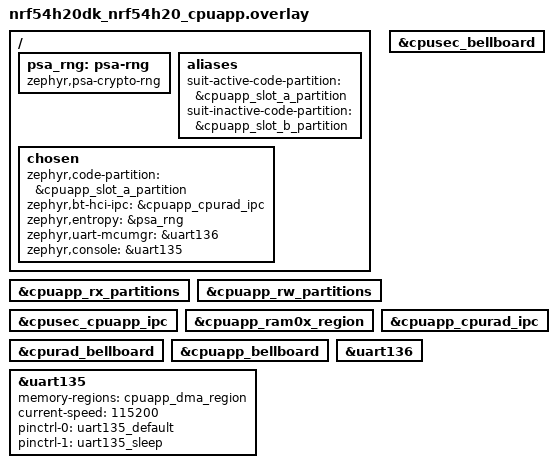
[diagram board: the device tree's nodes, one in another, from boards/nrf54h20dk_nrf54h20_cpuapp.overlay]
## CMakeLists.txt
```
#
# Copyright (c) 2025 Nordic Semiconductor ASA
#
# SPDX-License-Identifier: LicenseRef-Nordic-5-Clause
#

cmake_minimum_required(VERSION 3.13.1)

find_package(Zephyr REQUIRED HINTS $ENV{ZEPHYR_BASE})

project(suit_ab)

target_sources(app PRIVATE src/main.c)
target_sources(app PRIVATE src/suit_manifests_state.c)
target_sources(app PRIVATE src/suit_components_state.c)
target_sources(app PRIVATE src/device_management.c)
zephyr_library_include_directories(src)

zephyr_library_link_libraries(suit_manifest_variables)
zephyr_library_link_libraries(suit_ipuc)

# This project uses orginal sdk-zephyr C source code
target_include_directories(app PRIVATE $ENV{ZEPHYR_BASE}/samples/subsys/mgmt/mcumgr/smp_svr/src)
target_sources_ifdef(CONFIG_MCUMGR_TRANSPORT_BT app PRIVATE $ENV{ZEPHYR_BASE}/samples/subsys/mgmt/mcumgr/smp_svr/src/bluetooth.c)
```

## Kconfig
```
#
# Copyright (c) 2025 Nordic Semiconductor ASA
#
# SPDX-License-Identifier: LicenseRef-Nordic-5-Clause
#

config N_BLINKS
	int "Number of fast blinks"
	default 1

config ID_VAR_BOOT_STATUS
	int "Id of Manfiest-controlled variable representing a boot status"
	default 256

config ID_VAR_BOOT_PREFERENCE
	int "Id of Manfiest-controlled variable representing a boot prefrence"
	default 0

config ID_VAR_SET_TO_UPDATE
	int "Id of Manfiest-controlled variable representing image set to be updated"
	default 1

config ID_VAR_CONFIRM_SET_A
	int "Id of Manfiest-controlled variable representing after-update confirmation state for image set A"
	default 2

config ID_VAR_CONFIRM_SET_B
	int "Id of Manfiest-controlled variable representing after-update confirmation state for image set B"
	default 3

config EMULATE_APP_HEALTH_CHECK_FAILURE
	bool "Blocks confirmation of being healthy after the update"

source "Kconfig.zephyr"
```

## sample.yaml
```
#
# Copyright (c) 2025 Nordic Semiconductor ASA
#
# SPDX-License-Identifier: LicenseRef-Nordic-5-Clause
#

sample:
  name: SUIT A/B update through SMP sample
  description: Sample application that A/B updates firmware using SUIT and SMP protocol
common:
  platform_allow: nrf54h20dk/nrf54h20/cpuapp
  build_only: true
  sysbuild: true
tests:
  sample.suit.ab:
    extra_args:
    - SB_EXTRA_CONF_FILE="suit_mpi.conf"
    tags:
    - suit
    - bluetooth
    - ci_samples_suit
```

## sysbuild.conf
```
#
# Copyright (c) 2025 Nordic Semiconductor ASA
#
# SPDX-License-Identifier: LicenseRef-Nordic-5-Clause
#

SB_CONFIG_SUIT_ENVELOPE=y
SB_CONFIG_NETCORE_HCI_IPC=y

SB_CONFIG_SUIT_BUILD_AB_UPDATE=y
SB_CONFIG_SUIT_MPI_APP_LOCAL_2=y
SB_CONFIG_SUIT_MPI_RAD_LOCAL_2=y

SB_CONFIG_SUIT_BUILD_RECOVERY=y

SB_CONFIG_SUIT_ENVELOPE_APP_RECOVERY_TEMPLATE_FILENAME="app_recovery_envelope.jinja2"
```

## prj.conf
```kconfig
#
# Copyright (c) 2025 Nordic Semiconductor ASA
#
# SPDX-License-Identifier: LicenseRef-Nordic-5-Clause
#

# Enable DK LED library
CONFIG_DK_LIBRARY=y

# Enable mcumgr
CONFIG_NET_BUF=y
CONFIG_ZCBOR=y
CONFIG_ZCBOR_CANONICAL=y
CONFIG_MCUMGR=y
CONFIG_MCUMGR_SMP_LEGACY_RC_BEHAVIOUR=y
CONFIG_CRC=y

# Enable SUIT services
CONFIG_SUIT=y
CONFIG_SUIT_DFU_CANDIDATE_PROCESSING_FULL=y
CONFIG_MGMT_SUITFU=y
CONFIG_FLASH=y
CONFIG_FLASH_IPUC=y
CONFIG_SUIT_NORDIC_TOP_INDEPENDENT_UPDATE_FORBIDDEN=y
CONFIG_SUIT_CACHE_SDFW_IPUC=y

# Extended SUIT commands over USER group
CONFIG_MGMT_SUITFU_GRP_SUIT=y

# Enable bootloader identification within OS Management group
CONFIG_MCUMGR_GRP_OS=y
CONFIG_MCUMGR_GRP_OS_BOOTLOADER_INFO=y
CONFIG_MCUMGR_MGMT_NOTIFICATION_HOOKS=y
CONFIG_MCUMGR_GRP_OS_BOOTLOADER_INFO_HOOK=y

CONFIG_BT=y
CONFIG_BT_PERIPHERAL=y

# Allow for large Bluetooth data packets.
CONFIG_BT_L2CAP_TX_MTU=498
CONFIG_BT_BUF_ACL_RX_SIZE=502
CONFIG_BT_BUF_ACL_TX_SIZE=502

# Enable the Bluetooth mcumgr transport (unauthenticated).
CONFIG_MCUMGR_TRANSPORT_BT=y
CONFIG_MCUMGR_TRANSPORT_BT_PERM_RW=y
CONFIG_MCUMGR_TRANSPORT_BT_CONN_PARAM_CONTROL=y

# Enable logs over UART
CONFIG_LOG=y
CONFIG_SUIT_LOG_LEVEL_DBG=y
CONFIG_SSF_SUIT_SERVICE_LOG_LEVEL_WRN=y
CONFIG_MAIN_STACK_SIZE=4096
CONFIG_LOG_BUFFER_SIZE=8192

# Enable the mcumgr Packet Reassembly feature over Bluetooth and its configuration dependencies.
# MCUmgr buffer size is optimized to fit one SMP packet divided into five Bluetooth Write Commands,
# transmitted with the maximum possible MTU value: 498 bytes.
CONFIG_MCUMGR_TRANSPORT_BT_REASSEMBLY=y
CONFIG_MCUMGR_TRANSPORT_NETBUF_SIZE=2475
CONFIG_MCUMGR_TRANSPORT_WORKQUEUE_STACK_SIZE=4096

CONFIG_BT_DEVICE_NAME="SUIT AB Sample"

# Enable the serial mcumgr transport
CONFIG_BASE64=y
CONFIG_MCUMGR_TRANSPORT_UART=y
CONFIG_UART_MCUMGR_RX_BUF_SIZE=1040
CONFIG_MCUMGR_TRANSPORT_UART_MTU=1024
```

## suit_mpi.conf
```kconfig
#
# Copyright (c) 2025 Nordic Semiconductor ASA
#
# SPDX-License-Identifier: LicenseRef-Nordic-5-Clause
#
# ATTENTION! This is the right place to define a configuration for SUIT manifests in end-product
# and practically all config values included in that file shall be adjusted according
# to end-product needs/requirements.
# see: nrf/doc/nrf/app_dev/device_guides/nrf54h/ug_nrf54h20_suit_dfu.rst
#
# SB_CONFIG_SUIT_MPI_$(manifest)_VENDOR_NAME: Vendor-specific string *SHALL* be configured for *ALL* listed entries below.
# It may be the same value, i.e. "acme.com", for all entries, replacing existing "nordicsemi.com"
#
# SB_CONFIG_SUIT_MPI_$(manifest)_CLASS_NAME: Unique string prevents an update with firmware dedicated to other product
# Proposed schema: Manifest role + End Product model name.
# It *SHALL* be configured for *ALL* entries below, i.e.
# "nRF54H20_sample_root" replaced with "root_light_bulb_model_x123"
# "nRF54H20_sample_app" replaced with "app_A_light_bulb_model_x123"
# "nRF54H20_sample_app_local_2" replaced with "app_B_light_bulb_model_x123"
#
# Signature check policy for given manifest, select one of possible options:
# SB_CONFIG_SUIT_MPI_$(manifest)_SIGNATURE_CHECK_DISABLED=y, or
# SB_CONFIG_SUIT_MPI_$(manifest)_SIGNATURE_CHECK_ENABLED_ON_UPDATE=y, or
# SB_CONFIG_SUIT_MPI_$(manifest)_SIGNATURE_CHECK_ENABLED_ON_UPDATE_AND_BOOT=y

SB_CONFIG_SUIT_MPI_ROOT_VENDOR_NAME="nordicsemi.com"
SB_CONFIG_SUIT_MPI_ROOT_CLASS_NAME="nRF54H20_sample_root"
SB_CONFIG_SUIT_MPI_ROOT_DOWNGRADE_PREVENTION=y
SB_CONFIG_SUIT_MPI_ROOT_INDEPENDENT_UPDATE=y
SB_CONFIG_SUIT_MPI_ROOT_SIGNATURE_CHECK_ENABLED_ON_UPDATE_AND_BOOT=y

SB_CONFIG_SUIT_MPI_APP_RECOVERY=y
SB_CONFIG_SUIT_MPI_APP_RECOVERY_VENDOR_NAME="nordicsemi.com"
SB_CONFIG_SUIT_MPI_APP_RECOVERY_CLASS_NAME="nRF54H20_app_recovery"
SB_CONFIG_SUIT_MPI_APP_RECOVERY_DOWNGRADE_PREVENTION=y
SB_CONFIG_SUIT_MPI_APP_RECOVERY_INDEPENDENT_UPDATE=y
SB_CONFIG_SUIT_MPI_APP_RECOVERY_SIGNATURE_CHECK_ENABLED_ON_UPDATE_AND_BOOT=y

SB_CONFIG_SUIT_MPI_APP_LOCAL_1=y
SB_CONFIG_SUIT_MPI_APP_LOCAL_1_VENDOR_NAME="nordicsemi.com"
SB_CONFIG_SUIT_MPI_APP_LOCAL_1_CLASS_NAME="nRF54H20_sample_app"
SB_CONFIG_SUIT_MPI_APP_LOCAL_1_DOWNGRADE_PREVENTION=n
SB_CONFIG_SUIT_MPI_APP_LOCAL_1_INDEPENDENT_UPDATE=n
SB_CONFIG_SUIT_MPI_APP_LOCAL_1_SIGNATURE_CHECK_ENABLED_ON_UPDATE_AND_BOOT=y

SB_CONFIG_SUIT_MPI_APP_LOCAL_2=y
SB_CONFIG_SUIT_MPI_APP_LOCAL_2_VENDOR_NAME="nordicsemi.com"
SB_CONFIG_SUIT_MPI_APP_LOCAL_2_CLASS_NAME="nRF54H20_sample_app_local_2"
SB_CONFIG_SUIT_MPI_APP_LOCAL_2_DOWNGRADE_PREVENTION=n
SB_CONFIG_SUIT_MPI_APP_LOCAL_2_INDEPENDENT_UPDATE=n
SB_CONFIG_SUIT_MPI_APP_LOCAL_2_SIGNATURE_CHECK_ENABLED_ON_UPDATE_AND_BOOT=y

SB_CONFIG_SUIT_MPI_APP_LOCAL_3=n

SB_CONFIG_SUIT_MPI_RAD_RECOVERY=n

SB_CONFIG_SUIT_MPI_RAD_LOCAL_1=y
SB_CONFIG_SUIT_MPI_RAD_LOCAL_1_VENDOR_NAME="nordicsemi.com"
SB_CONFIG_SUIT_MPI_RAD_LOCAL_1_CLASS_NAME="nRF54H20_sample_rad"
SB_CONFIG_SUIT_MPI_RAD_LOCAL_1_DOWNGRADE_PREVENTION=n
SB_CONFIG_SUIT_MPI_RAD_LOCAL_1_INDEPENDENT_UPDATE=n
SB_CONFIG_SUIT_MPI_RAD_LOCAL_1_SIGNATURE_CHECK_ENABLED_ON_UPDATE_AND_BOOT=y

SB_CONFIG_SUIT_MPI_RAD_LOCAL_2=y
SB_CONFIG_SUIT_MPI_RAD_LOCAL_2_VENDOR_NAME="nordicsemi.com"
SB_CONFIG_SUIT_MPI_RAD_LOCAL_2_CLASS_NAME="nRF54H20_sample_rad_local_2"
SB_CONFIG_SUIT_MPI_RAD_LOCAL_2_DOWNGRADE_PREVENTION=n
SB_CONFIG_SUIT_MPI_RAD_LOCAL_2_INDEPENDENT_UPDATE=n
SB_CONFIG_SUIT_MPI_RAD_LOCAL_2_SIGNATURE_CHECK_ENABLED_ON_UPDATE_AND_BOOT=y
```

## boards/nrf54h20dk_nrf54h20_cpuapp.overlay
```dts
/*
 * Copyright (c) 2025 Nordic Semiconductor ASA
 *
 * SPDX-License-Identifier: LicenseRef-Nordic-5-Clause
 */

#include "../sysbuild/nrf54h20dk_nrf54h20_memory_map.dtsi"

/* Enable partitions, belonging to the application domain. */
&cpuapp_rx_partitions {
	status = "okay";
};

&cpuapp_rw_partitions {
	status = "okay";
};

/* Enable IPC: Application <-> Secure */
&cpusec_cpuapp_ipc {
	status = "okay";
};

&cpuapp_ram0x_region {
	status = "okay";
};

&cpusec_bellboard {
	status = "okay";
};

/* Enable IPC: Application <-> Radio */
&cpuapp_cpurad_ipc {
	status = "okay";
};

&cpurad_bellboard {
	status = "okay";
};

&cpuapp_bellboard {
	status = "okay";
};

/* Disable HW flow control on the UART 0 */
&uart136 {
	/delete-property/ hw-flow-control;
};

/ {
	psa_rng: psa-rng {
		compatible = "zephyr,psa-crypto-rng";
		status = "okay";
	};

	aliases {
		suit-active-code-partition = &cpuapp_slot_a_partition;
		suit-inactive-code-partition = &cpuapp_slot_b_partition;
	};

	chosen {
		zephyr,code-partition = &cpuapp_slot_a_partition;
		zephyr,bt-hci-ipc = &cpuapp_cpurad_ipc;
		zephyr,entropy = &psa_rng;
		zephyr,uart-mcumgr = &uart136;
	};
};

/* UART 1 is configured for App Core console output. In order to use it for other
 * purpose, i.e. to output logs form the Radio core, remove section below.
 */
&uart135 {
	status = "okay";
	memory-regions = <&cpuapp_dma_region>;
	current-speed = <115200>;
	pinctrl-0 = <&uart135_default>;
	pinctrl-1 = <&uart135_sleep>;
	pinctrl-names = "default", "sleep";

	/delete-property/ hw-flow-control;
};

/ {
	chosen {
		zephyr,console = &uart135;
	};
};
```

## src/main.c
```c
/*
 * Copyright (c) 2025 Nordic Semiconductor ASA
 *
 * SPDX-License-Identifier: LicenseRef-Nordic-5-Clause
 */

#include <suit_manifests_state.h>
#include <suit_components_state.h>
#include <device_management.h>

#include "common.h"
#include <zephyr/kernel.h>
#include <dk_buttons_and_leds.h>
#include <zephyr/logging/log.h>


#define STATUS_LEDS_THREAD_STACK_SIZE 512
#define STATUS_LEDS_THREAD_PRIORITY (CONFIG_NUM_PREEMPT_PRIORITIES - 1)
K_THREAD_STACK_DEFINE(status_leds_thread_stack_area, STATUS_LEDS_THREAD_STACK_SIZE);

LOG_MODULE_REGISTER(AB, CONFIG_SUIT_LOG_LEVEL);

static void button_handler(uint32_t button_state, uint32_t has_changed)
{
	if ((has_changed & DK_BTN4_MSK) && (button_state & DK_BTN4_MSK)) {
		toggle_preferred_boot_set();
	}
}

/**
 * Meaning of LED states on LED-s 3 and 4:
 *
 * 1) Both LEDs are on all the time: Normal mode, not degraded.
 * 2) Both leds blinking at the same time: Degraded mode.
 * 3) Only one led blinking:  Degraded mode, no radio.
 * 4) LEDs blinking one after the other:  Device in recovery mode.
 * 5) Both LEDs off:  Unrecognized state.
 */
void status_leds_thread_entry_point(void *p1, void *p2, void *p3)
{
	uint8_t sequence_led3 = 0b00;
	uint8_t sequence_led4 = 0b00;
	uint32_t boot_status = device_boot_status_get();
	uint8_t cnt = 0;

	if (device_is_in_recovery_mode()) {
		sequence_led3 = 0b01;
		sequence_led4 = 0b10;
	} else if (boot_status == BOOT_STATUS_A || boot_status == BOOT_STATUS_B) {
		sequence_led3 = 0b11;
		sequence_led4 = 0b11;
	} else if (boot_status == BOOT_STATUS_A_DEGRADED || boot_status == BOOT_STATUS_B_DEGRADED) {
		sequence_led3 = 0b10;
		sequence_led4 = 0b10;
	} else if (boot_status == BOOT_STATUS_A_NO_RADIO || boot_status == BOOT_STATUS_B_NO_RADIO) {
		sequence_led3 = 0b01;
		sequence_led4 = 0b00;
	}

	while (1) {
		if (sequence_led3 & (1 << cnt)) {
			dk_set_led_on(DK_LED3);
		} else {
			dk_set_led_off(DK_LED3);
		}

		if (sequence_led4 & (1 << cnt)) {
			dk_set_led_on(DK_LED4);
		} else {
			dk_set_led_off(DK_LED4);
		}

		k_msleep(250);

		cnt = (cnt + 1) % 2;
	}
}

int main(void)
{
	char *app_img_name = NULL;
	int ret = 0;

	ret = dk_leds_init();
	if (ret) {
		LOG_ERR("Cannot init LEDs (err: %d)\r\n", ret);
	}

	ret = dk_buttons_init(button_handler);
	if (ret) {
		LOG_ERR("Cannot init buttons (err: %d)", ret);
	}

	dk_set_led_on(DK_LED1);
	dk_set_led_on(DK_LED2);

	if (IS_ENABLED(CONFIG_MCUMGR_TRANSPORT_BT)) {
		start_smp_bluetooth_adverts();
		k_msleep(250);
	}
	printk("\n");

	suit_mainfests_state_report();
	printk("\n");

	int blinking_led = DK_LED1;

	if (DT_SAME_NODE(DT_ALIAS(suit_active_code_partition),
			 DT_NODELABEL(cpuapp_slot_a_partition))) {
		app_img_name = "A";
	} else {
		app_img_name = "B";
		blinking_led = DK_LED2;
	}

	printk("---------------------------------------------------\n");
	printk("A/B Hello world from %s, blinks: %d, img: %s\n", CONFIG_BOARD, CONFIG_N_BLINKS,
	       app_img_name);
	printk("BUILD: %s %s\n", __DATE__, __TIME__);
	printk("---------------------------------------------------\n\n");

	suit_components_state_report();
	printk("\n");

	device_boot_state_report();
	printk("\n");

	device_healthcheck();

	struct k_thread status_leds_thread_data;

	k_thread_create(&status_leds_thread_data, status_leds_thread_stack_area,
			K_THREAD_STACK_SIZEOF(status_leds_thread_stack_area),
			status_leds_thread_entry_point,
			NULL, NULL, NULL,
			STATUS_LEDS_THREAD_PRIORITY, 0, K_NO_WAIT);

	while (1) {
		for (int i = 0; i < CONFIG_N_BLINKS; i++) {
			dk_set_led_off(blinking_led);
			k_msleep(250);
			dk_set_led_on(blinking_led);
			k_msleep(250);
		}

		k_msleep(5000);
	}

	return 0;
}
```

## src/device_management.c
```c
/*
 * Copyright (c) 2025 Nordic Semiconductor ASA
 *
 * SPDX-License-Identifier: LicenseRef-Nordic-5-Clause
 */

#include <zephyr/kernel.h>
#include <suit_manifest_variables.h>
#include <device_management.h>
#include <zephyr/logging/log.h>
#include <sdfw/sdfw_services/suit_service.h>
#include <zephyr/bluetooth/bluetooth.h>
#include <mpsl/flash_sync_rpc_host.h>

LOG_MODULE_DECLARE(AB, CONFIG_SUIT_LOG_LEVEL);

#define NOT_CONFIRMED 2
#define CONFIRMED     3

#define BOOT_PREFERENCE_A 1
#define BOOT_PREFERENCE_B 2

/** @brief Radio firmware self test
 *
 * @details
 * End-device specific self test should be implemented here.
 */
static bool radio_domain_healthy(void)
{
	return bt_is_ready();
}

/** @brief Application firmware self test
 *
 * @details
 * End-device specific self test should be implemented here. Enabling
 * CONFIG_EMULATE_APP_HEALTH_CHECK_FAILURE allows to emulate a faulty
 * firmware, unable to confirm its health, and ultimately to test
 * a rollback to previous firmware after the update.
 */
static bool app_domain_healthy(void)
{
	if (IS_ENABLED(CONFIG_EMULATE_APP_HEALTH_CHECK_FAILURE)) {
		return false;
	}

	return true;
}

bool device_is_in_recovery_mode(void)
{
	static suit_boot_mode_t mode = SUIT_BOOT_MODE_UNKNOWN;
	suit_plat_err_t err = SUIT_PLAT_SUCCESS;

	if (mode == SUIT_BOOT_MODE_UNKNOWN) {
		err = suit_boot_mode_read(&mode);
		if (err != SUIT_PLAT_SUCCESS) {
			LOG_ERR("Cannot get the boot mode");
			mode = SUIT_BOOT_MODE_FAIL_STARTUP;
		}
	}

	return (mode == SUIT_BOOT_MODE_POST_INVOKE_RECOVERY);
}

uint32_t device_boot_status_get(void)
{
	suit_plat_err_t err = SUIT_PLAT_SUCCESS;
	static uint32_t mfst_var_boot_status;

	if (mfst_var_boot_status == 0) {
		err = suit_mfst_var_get(CONFIG_ID_VAR_BOOT_STATUS, &mfst_var_boot_status);
		if (err != SUIT_PLAT_SUCCESS) {
			LOG_ERR("Cannot get a device boot status");
			mfst_var_boot_status = BOOT_STATUS_CANNOT_BOOT;
		}
	}

	return mfst_var_boot_status;
}

void device_healthcheck(void)
{
	suit_plat_err_t err = SUIT_PLAT_SUCCESS;
	char *img_set = NULL;
	uint32_t mfst_var_boot_status = BOOT_STATUS_CANNOT_BOOT;
	uint32_t mfst_var_confirm_status = CONFIRMED;
	uint32_t id_var_confirm_set = CONFIG_ID_VAR_CONFIRM_SET_A;

	mfst_var_boot_status = device_boot_status_get();

	if (mfst_var_boot_status == BOOT_STATUS_CANNOT_BOOT) {
		return;
	}

	if (mfst_var_boot_status == BOOT_STATUS_A_NO_RADIO
	    || mfst_var_boot_status == BOOT_STATUS_B_NO_RADIO) {
		/* Disable flash synchronization with radio core,
		 * as radio core is not running.
		 */
		flash_sync_rpc_host_sync_enable(false);
	}

	/* Confirming only in non-degraded boot states
	 */
	if (DT_SAME_NODE(DT_ALIAS(suit_active_code_partition),
			 DT_NODELABEL(cpuapp_slot_a_partition))) {
		if (mfst_var_boot_status != BOOT_STATUS_A) {
			return;
		}
		img_set = "A";
	} else {
		if (mfst_var_boot_status != BOOT_STATUS_B) {
			return;
		}

		img_set = "B";
		id_var_confirm_set = CONFIG_ID_VAR_CONFIRM_SET_B;
	}

	err = suit_mfst_var_get(id_var_confirm_set, &mfst_var_confirm_status);
	if (err != SUIT_PLAT_SUCCESS) {
		LOG_ERR("Cannot get a confirm status");
		return;
	}

	if (mfst_var_confirm_status != CONFIRMED) {
		LOG_INF("Image set %s not confirmed yet, testing...", img_set);

		bool healthy = true;

		if (!radio_domain_healthy()) {
			LOG_ERR("Radio domain is NOT healthy");
			/* Disable flash synchronization with radio core,
			 * as radio core is not operational.
			 */
			flash_sync_rpc_host_sync_enable(false);
			healthy = false;
		}

		if (!app_domain_healthy()) {
			LOG_ERR("App domain is NOT healthy");
			healthy = false;
		}

		if (!healthy) {
			LOG_ERR("Reboot the device to try to boot from previous firmware");
			return;
		}

		LOG_INF("Confirming...");
		err = suit_mfst_var_set(id_var_confirm_set, CONFIRMED);
		if (err == SUIT_PLAT_SUCCESS) {
			LOG_INF("Confirmed\n");
		}
	}
}

void toggle_preferred_boot_set(void)
{
	suit_plat_err_t err = SUIT_PLAT_SUCCESS;
	uint32_t mfst_var_boot_preference = 0;

	err = suit_mfst_var_get(CONFIG_ID_VAR_BOOT_PREFERENCE, &mfst_var_boot_preference);
	if (err != SUIT_PLAT_SUCCESS) {
		LOG_ERR("Cannot get current boot preference");
		return;
	}

	if (mfst_var_boot_preference == BOOT_PREFERENCE_B) {
		LOG_INF("Changing a boot preference (b -> A)");
		mfst_var_boot_preference = BOOT_PREFERENCE_A;
	} else {
		LOG_INF("Changing a boot preference (a -> B)");
		mfst_var_boot_preference = BOOT_PREFERENCE_B;
	}

	err = suit_mfst_var_set(CONFIG_ID_VAR_BOOT_PREFERENCE, mfst_var_boot_preference);
	if (err == SUIT_PLAT_SUCCESS) {
		LOG_INF("restart the device to enforce\n");
	} else {
		LOG_ERR("Cannot set a boot preference");
	}
}

void device_boot_state_report(void)
{
	suit_plat_err_t err = SUIT_PLAT_SUCCESS;
	uint32_t mfst_var_boot_preference = 0;
	uint32_t mfst_var_boot_status = 0;
	uint32_t mfst_var_confirm_set_a = 0;
	uint32_t mfst_var_confirm_set_b = 0;

	if (device_is_in_recovery_mode()) {
		printk("Boot in RECOVERY mode, probably the root manifest is damaged!\n");
	}

	err = suit_mfst_var_get(CONFIG_ID_VAR_BOOT_PREFERENCE, &mfst_var_boot_preference);
	if (err == SUIT_PLAT_SUCCESS) {
		if (mfst_var_boot_preference == BOOT_PREFERENCE_B) {
			printk("Boot preference: set B\n");
		} else {
			printk("Boot preference: set A\n");
		}
	}

	mfst_var_boot_status = device_boot_status_get();

	if (mfst_var_boot_status == BOOT_STATUS_A) {
		printk("Boot status: image set A active\n");
	} else if (mfst_var_boot_status == BOOT_STATUS_B) {
		printk("Boot status: image set B active\n");
	} else if (mfst_var_boot_status == BOOT_STATUS_A_DEGRADED) {
		printk("Boot status: image set A active, degraded mode\n");
	} else if (mfst_var_boot_status == BOOT_STATUS_B_DEGRADED) {
		printk("Boot status: app image B active, degraded mode\n");
	} else if (mfst_var_boot_status == BOOT_STATUS_A_NO_RADIO) {
		printk("Boot status: app image A active, no radio, degraded mode\n");
	} else if (mfst_var_boot_status == BOOT_STATUS_B_NO_RADIO) {
		printk("Boot status: app image B active, no radio, degraded mode\n");
	} else {
		printk("Boot status: unrecognized\n");
	}

	err = suit_mfst_var_get(CONFIG_ID_VAR_CONFIRM_SET_A, &mfst_var_confirm_set_a);
	if (err == SUIT_PLAT_SUCCESS) {
		if (mfst_var_confirm_set_a == NOT_CONFIRMED) {
			printk("Confirm status set A: not confirmed\n");
		} else if (mfst_var_confirm_set_a == CONFIRMED) {
			printk("Confirm status set A: confirmed\n");
		} else {
			printk("Confirm status set A: just installed\n");
		}
	}

	err = suit_mfst_var_get(CONFIG_ID_VAR_CONFIRM_SET_B, &mfst_var_confirm_set_b);
	if (err == SUIT_PLAT_SUCCESS) {
		if (mfst_var_confirm_set_b == NOT_CONFIRMED) {
			printk("Confirm status set B: not confirmed\n");
		} else if (mfst_var_confirm_set_b == CONFIRMED) {
			printk("Confirm status set B: confirmed\n");
		} else {
			printk("Confirm status set B: just installed\n");
		}
	}
}
```

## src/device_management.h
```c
/*
 * Copyright (c) 2025 Nordic Semiconductor ASA
 *
 * SPDX-License-Identifier: LicenseRef-Nordic-5-Clause
 */

#ifndef DEVICE_MANAGEMANT_H__
#define DEVICE_MANAGEMANT_H__

#ifdef __cplusplus
extern "C" {
#endif

#include <stdint.h>
#include <stdbool.h>

/* Definitions below reflect a way of usage of manifest-controlled variables
 * in this specific application.
 */
#define BOOT_STATUS_A		1
#define BOOT_STATUS_B		2
#define BOOT_STATUS_A_DEGRADED	3
#define BOOT_STATUS_B_DEGRADED	4
#define BOOT_STATUS_A_NO_RADIO	5
#define BOOT_STATUS_B_NO_RADIO	6
#define BOOT_STATUS_CANNOT_BOOT 7

/** @brief Performs a self-tests and confirms
 * successful firmware update, if needed
 */
void device_healthcheck(void);

/** @brief Toggles preferred boot set
 */
void toggle_preferred_boot_set(void);

/** @brief Displays information about state of image sets,
 * boot preference and a boot status
 */
void device_boot_state_report(void);

/** @brief Checks if the device is in recovery mode
 */
bool device_is_in_recovery_mode(void);

/** @brief Gets the boot status of the device
 */
uint32_t device_boot_status_get(void);

#endif /* DEVICE_MANAGEMANT_H__ */
```

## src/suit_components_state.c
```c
/*
 * Copyright (c) 2025 Nordic Semiconductor ASA
 *
 * SPDX-License-Identifier: LicenseRef-Nordic-5-Clause
 */

#include <zephyr/kernel.h>
#include <suit_ipuc.h>
#include <suit_metadata.h>
#include <suit_plat_decode_util.h>
#include <suit_components_state.h>

void suit_components_state_report(void)
{
	suit_plat_err_t err = SUIT_PLAT_SUCCESS;
	size_t count = 0;

	err = suit_ipuc_get_count(&count);
	if (err == SUIT_PLAT_SUCCESS) {

		printk("In-place updateable components:\n");
		for (size_t idx = 0; idx < count; idx++) {
			struct zcbor_string component_id;
			uint8_t component_id_data[32];
			suit_manifest_role_t role = SUIT_MANIFEST_UNKNOWN;

			component_id.value = component_id_data;
			component_id.len = sizeof(component_id_data);
			err = suit_ipuc_get_info(idx, &component_id, &role);
			if (err == SUIT_PLAT_SUCCESS) {
				suit_component_type_t component_type =
					SUIT_COMPONENT_TYPE_UNSUPPORTED;

				suit_plat_decode_component_type(&component_id, &component_type);
				if (component_type == SUIT_COMPONENT_TYPE_MEM) {
					uint8_t core_id = 0;
					intptr_t run_address = 0;
					size_t slot_size = 0;

					suit_plat_decode_component_id(&component_id, &core_id,
								      &run_address, &slot_size);

					printk("MEM, 0x%08X, %d bytes, core: %d, mfst role: "
					       "0x%02X\n",
					       (unsigned int)run_address, slot_size, core_id, role);

				} else {
					printk("component_type: %d, mfst role: 0x%02X\n",
					       component_type, role);
				}
			}
		}
	}
}
```

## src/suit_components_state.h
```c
/*
 * Copyright (c) 2025 Nordic Semiconductor ASA
 *
 * SPDX-License-Identifier: LicenseRef-Nordic-5-Clause
 */

#ifndef SUIT_COMPONENTS_STATE_H__
#define SUIT_COMPONENTS_STATE_H__

#ifdef __cplusplus
extern "C" {
#endif

/** @brief Displays information about known SUIT components
 */
void suit_components_state_report(void);

#endif /* SUIT_COMPONENTS_STATE_H__ */
```

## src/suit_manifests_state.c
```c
/*
 * Copyright (c) 2025 Nordic Semiconductor ASA
 *
 * SPDX-License-Identifier: LicenseRef-Nordic-5-Clause
 */

#include <stdint.h>
#include <zephyr/kernel.h>
#include <sdfw/sdfw_services/suit_service.h>
#include <suit_manifests_state.h>

#define MAX_MANIFESTS 15

static void report_class_id(uint8_t *cid)
{

	static const uint8_t nRF54H20_sample_root_cid[] = {0x3f, 0x6a, 0x3a, 0x4d, 0xcd, 0xfa,
							   0x58, 0xc5, 0xac, 0xce, 0xf9, 0xf5,
							   0x84, 0xc4, 0x11, 0x24};

	static const uint8_t nRF54H20_sample_app_recovery_cid[] = {
		0xA3, 0x7B, 0x77, 0xB0, 0x87, 0x0E, 0x57, 0x49,
		0xA8, 0x64, 0xF1, 0x44, 0x4A, 0xAF, 0xF5, 0x47};

	static const uint8_t nRF54H20_sample_app_cid[] = {0x08, 0xc1, 0xb5, 0x99, 0x55, 0xe8,
							  0x5f, 0xbc, 0x9e, 0x76, 0x7b, 0xc2,
							  0x9c, 0xe1, 0xb0, 0x4d};
	static const uint8_t nRF54H20_sample_app2_cid[] = {0x51, 0xde, 0x10, 0xb8, 0xee, 0x2e,
							   0x5b, 0x4b, 0x80, 0xee, 0x53, 0x4a,
							   0x4a, 0x3c, 0x04, 0xfc};

	static const uint8_t nRF54H20_sample_app3_cid[] = {0x2D, 0xCA, 0x15, 0xA5, 0xA3, 0x2E,
							   0x5A, 0x71, 0xBE, 0x54, 0xBA, 0x07,
							   0xBB, 0xAF, 0xAE, 0x27};

	static const uint8_t nRF54H20_sample_rad_recovery_cid[] = {
		0x58, 0x00, 0x98, 0xAE, 0xB2, 0x40, 0x50, 0x66,
		0xAF, 0x45, 0x57, 0x33, 0x25, 0xFC, 0x39, 0xF6};

	static const uint8_t nRF54H20_sample_rad_cid[] = {0x81, 0x6a, 0xa0, 0xa0, 0xaf, 0x11,
							  0x5e, 0xf2, 0x85, 0x8a, 0xfe, 0xb6,
							  0x68, 0xb2, 0xe9, 0xc9};
	static const uint8_t nRF54H20_sample_rad2_cid[] = {0x0a, 0xa4, 0xbe, 0x57, 0xb3, 0x1e,
							   0x57, 0x9c, 0xab, 0x81, 0x13, 0xbd,
							   0x90, 0xe1, 0x6e, 0xf7};
	static const uint8_t nRF54H20_nordic_top_cid[] = {0xf0, 0x3d, 0x38, 0x5e, 0xa7, 0x31,
							  0x56, 0x05, 0xb1, 0x5d, 0x03, 0x7f,
							  0x6d, 0xa6, 0x09, 0x7f};
	static const uint8_t nRF54H20_sys_cid[] = {0xc0, 0x8a, 0x25, 0xd7, 0x35, 0xe6, 0x59, 0x2c,
						   0xb7, 0xad, 0x43, 0xac, 0xc8, 0xd1, 0xd1, 0xc8};
	static const uint8_t nRF54H20_sec_cid[] = {0xd9, 0x6b, 0x40, 0xb7, 0x09, 0x2b, 0x5c, 0xd1,
						   0xa5, 0x9f, 0x9a, 0xf8, 0x0c, 0x33, 0x7e, 0xba};

	printk(" class ID:  %02X%02X%02X%02X-%02X%02X-%02X%02X-%02X%02X-%02X%02X%02X%02X%02X%02X",
	       cid[0], cid[1], cid[2], cid[3], cid[4], cid[5], cid[6], cid[7], cid[8], cid[9],
	       cid[10], cid[11], cid[12], cid[13], cid[14], cid[15]);

	if (memcmp(nRF54H20_sample_root_cid, cid, 16) == 0) {
		printk(" (nRF54H20_sample_root) - TO BE CHANGED for end product!!!\n");
	} else if (memcmp(nRF54H20_sample_app_recovery_cid, cid, 16) == 0) {
		printk(" (nRF54H20_app_recovery) - TO BE CHANGED for end product!!!\n");
	} else if (memcmp(nRF54H20_sample_app_cid, cid, 16) == 0) {
		printk(" (nRF54H20_sample_app) - TO BE CHANGED for end product!!!\n");
	} else if (memcmp(nRF54H20_sample_app2_cid, cid, 16) == 0) {
		printk(" (nRF54H20_sample_app_local_2) - TO BE CHANGED for end product!!!\n");
	} else if (memcmp(nRF54H20_sample_app3_cid, cid, 16) == 0) {
		printk(" (nRF54H20_sample_app_local_3) - TO BE CHANGED for end product!!!\n");
	} else if (memcmp(nRF54H20_sample_rad_recovery_cid, cid, 16) == 0) {
		printk(" (nRF54H20_sample_rad_recovery) - TO BE CHANGED for end product!!!\n");
	} else if (memcmp(nRF54H20_sample_rad_cid, cid, 16) == 0) {
		printk(" (nRF54H20_sample_rad) - TO BE CHANGED for end product!!!\n");
	} else if (memcmp(nRF54H20_sample_rad2_cid, cid, 16) == 0) {
		printk(" (nRF54H20_sample_rad2) - TO BE CHANGED for end product!!!\n");
	} else if (memcmp(nRF54H20_nordic_top_cid, cid, 16) == 0) {
		printk(" (nRF54H20_nordic_top)\n");
	} else if (memcmp(nRF54H20_sys_cid, cid, 16) == 0) {
		printk(" (nRF54H20_sys)\n");
	} else if (memcmp(nRF54H20_sec_cid, cid, 16) == 0) {
		printk(" (nRF54H20_sec)\n");
	} else {
		printk("\n");
	}
}

static void report_vendor_id(uint8_t *vid, suit_manifest_role_t role)
{

	static const uint8_t nordic_vid[] = {0x76, 0x17, 0xda, 0xa5, 0x71, 0xfd, 0x5a, 0x85,
					     0x8f, 0x94, 0xe2, 0x8d, 0x73, 0x5c, 0xe9, 0xf4};

	printk(" vendor ID: %02X%02X%02X%02X-%02X%02X-%02X%02X-%02X%02X-%02X%02X%02X%02X%02X%02X",
	       vid[0], vid[1], vid[2], vid[3], vid[4], vid[5], vid[6], vid[7], vid[8], vid[9],
	       vid[10], vid[11], vid[12], vid[13], vid[14], vid[15]);

	if (memcmp(nordic_vid, vid, 16) == 0) {

		if (((role & 0xF0) == SUIT_MANIFEST_DOMAIN_APP) ||
		    ((role & 0xF0) == SUIT_MANIFEST_DOMAIN_RAD)) {
			printk(" (nordicsemi.com) - TO BE CHANGED for end product!!!\n");
		} else {
			printk(" (nordicsemi.com)\n");
		}
	} else {
		printk("\n");
	}
}

static void report_role(suit_manifest_role_t role)
{
	printk("   role: 0x%02x", role);

	if (role == SUIT_MANIFEST_SEC_TOP) {
		printk(" (Nordic Top Manifest)\n");
	} else if (role == SUIT_MANIFEST_SEC_SDFW) {
		printk(" (SDFW and SDFW recovery updates)\n");
	} else if (role == SUIT_MANIFEST_SEC_SYSCTRL) {
		printk(" (System Controller Manifest)\n");
	} else if (role == SUIT_MANIFEST_APP_ROOT) {
		printk(" (Root Manifest)\n");
	} else if (role == SUIT_MANIFEST_APP_RECOVERY) {
		printk(" (Application Recovery Manifest)\n");
	} else if (role >= SUIT_MANIFEST_APP_LOCAL_1 && role <= SUIT_MANIFEST_APP_LOCAL_3) {
		printk(" (Application Local Manifest)\n");
	} else if (role == SUIT_MANIFEST_RAD_RECOVERY) {
		printk(" (Radio Recovery Manifest)\n");
	} else if (role >= SUIT_MANIFEST_RAD_LOCAL_1 && role <= SUIT_MANIFEST_RAD_LOCAL_2) {
		printk(" (Radio Local Manifest)\n");
	} else {
		printk("\n");
	}
}

static void report_downgrade_prevention_policy(suit_downgrade_prevention_policy_t policy)
{
	printk("   downgrade prevention policy:");

	if (policy == SUIT_DOWNGRADE_PREVENTION_DISABLED) {
		printk(" downgrade allowed\n");
	} else if (policy == SUIT_DOWNGRADE_PREVENTION_ENABLED) {
		printk(" downgrade forbidden\n");
	} else {
		printk(" invalid!\n");
	}
}

static void report_independent_updateability_policy(suit_independent_updateability_policy_t policy)
{
	printk("   independent updateability policy:");

	if (policy == SUIT_INDEPENDENT_UPDATE_DENIED) {
		printk(" independent update forbidden\n");
	} else if (policy == SUIT_INDEPENDENT_UPDATE_ALLOWED) {
		printk(" independent update allowed\n");
	} else {
		printk(" invalid!\n");
	}
}

static void report_signature_verification_policy(suit_signature_verification_policy_t policy)
{
	printk("   signature verification policy:");

	if (policy == SUIT_SIGNATURE_CHECK_DISABLED) {
		printk(" signature verification disabled\n");
	} else if (policy == SUIT_SIGNATURE_CHECK_ENABLED_ON_UPDATE) {
		printk(" signature verification on update\n");
	} else if (policy == SUIT_SIGNATURE_CHECK_ENABLED_ON_UPDATE_AND_BOOT) {
		printk(" signature verification on update and boot\n");
	} else {
		printk(" invalid!\n");
	}
}

static void report_digest(uint8_t *digest, size_t size, int digest_alg_id)
{

	if (size >= 8) {
		printk("   digest: %02X%02X%02X%02X..%02X%02X%02X%02X", digest[0], digest[1],
		       digest[2], digest[3], digest[size - 4], digest[size - 3], digest[size - 2],
		       digest[size - 1]);
	}

	if (digest_alg_id == -16) {
		printk(" (sha-256)\n");
	} else if (digest_alg_id == -18) {
		printk(" (shake128)\n");
	} else if (digest_alg_id == -43) {
		printk(" (sha-384)\n");
	} else if (digest_alg_id == -44) {
		printk(" (sha-512)\n");
	} else if (digest_alg_id == -45) {
		printk(" (shake256)\n");
	} else {
		printk("\n");
	}
}

static void report_digest_status(int status)
{
	if (status == 2) {
		printk("   signature check not performed\n");
	} else if (status == 3) {
		printk("   signature check failed!\n");
	} else if (status == 4) {
		printk("   signature check passed\n");
	}
}

static void report_sequence_number(int sequence_number)
{
	printk("   sequence number: %d\n", sequence_number);
}

static void report_semver(int32_t *raw, size_t len)
{

	int32_t major = 0;
	int32_t minor = 0;
	int32_t patch = 0;
	int32_t release_type = 0;
	int32_t release_type_idx = 0;
	int32_t pre_release_number = 0;

	if (len == 0 || len > 5) {
		return;
	}

	if (raw[0] < 0) {
		return;
	}

	for (size_t idx = 0; idx < len; idx++) {
		int32_t element = raw[idx];

		if (element >= 0 && release_type == 0) {
			switch (idx) {
			case 0:
				major = element;
				break;
			case 1:
				minor = element;
				break;
			case 2:
				patch = element;
				break;
			default:
				return;
			}

		} else if (element < 0 && element >= -3 && release_type == 0) {
			release_type = element;
			release_type_idx = idx;
		} else if (element >= 0 && release_type < 0 && idx - 1 == release_type_idx) {
			pre_release_number = element;
		} else {
			return;
		}
	}

	printk("   semantic version: %d.%d.%d", major, minor, patch);

	if (release_type == -1) {
		printk("-rc.%d\n", pre_release_number);
	} else if (release_type == -2) {
		printk("-beta.%d\n", pre_release_number);
	} else if (release_type == -3) {
		printk("-alpha.%d\n", pre_release_number);
	} else {
		printk("\n");
	}
}

void suit_mainfests_state_report(void)
{

	suit_plat_err_t rc;
	suit_manifest_role_t roles[MAX_MANIFESTS] = {0};
	size_t class_info_count = MAX_MANIFESTS;

	rc = suit_get_supported_manifest_roles(roles, &class_info_count);
	if (rc != SUIT_PLAT_SUCCESS) {
		return;
	}

	printk("-------------------------------------------------------------\n");

	for (size_t i = 0; i < class_info_count; i++) {

		suit_manifest_role_t role = roles[i];
		suit_ssf_manifest_class_info_t class_info = {0};

		rc = suit_get_supported_manifest_info(role, &class_info);
		if (rc != SUIT_PLAT_SUCCESS) {
			continue;
		}

		report_class_id(class_info.class_id.raw);
		report_vendor_id(class_info.vendor_id.raw, class_info.role);
		report_role(class_info.role);
		report_downgrade_prevention_policy(class_info.downgrade_prevention_policy);
		report_independent_updateability_policy(
			class_info.independent_updateability_policy);
		report_signature_verification_policy(class_info.signature_verification_policy);

		unsigned int seq_num = 0;
		suit_semver_raw_t semver_raw = {0};
		suit_digest_status_t digest_status = SUIT_DIGEST_UNKNOWN;
		int digest_alg_id = 0;
		uint8_t digest_buf[64] = {0};
		suit_plat_mreg_t digest;

		digest.mem = digest_buf;
		digest.size = sizeof(digest_buf);

		rc = suit_get_installed_manifest_info(&class_info.class_id, &seq_num, &semver_raw,
						      &digest_status, &digest_alg_id, &digest);

		if (rc == SUIT_PLAT_ERR_NOT_FOUND || digest.size == 0) {
			printk("   Manifest not installed or damaged!\n\n");
			continue;
		} else if (rc != SUIT_PLAT_SUCCESS) {
			printk("\n");
			continue;
		}

		report_digest(digest_buf, digest.size, digest_alg_id);
		report_digest_status(digest_status);
		report_sequence_number(seq_num);
		report_semver(semver_raw.raw, semver_raw.len);

		printk("\n");
	}
}
```

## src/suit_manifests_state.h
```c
/*
 * Copyright (c) 2025 Nordic Semiconductor ASA
 *
 * SPDX-License-Identifier: LicenseRef-Nordic-5-Clause
 */

#ifndef SUIT_MANIFESTS_STATE_H__
#define SUIT_MANIFESTS_STATE_H__

#ifdef __cplusplus
extern "C" {
#endif

/** @brief Displays information about SUIT manifests
 */
void suit_mainfests_state_report(void);

#endif /* SUIT_MANIFESTS_STATE_H__ */
```
